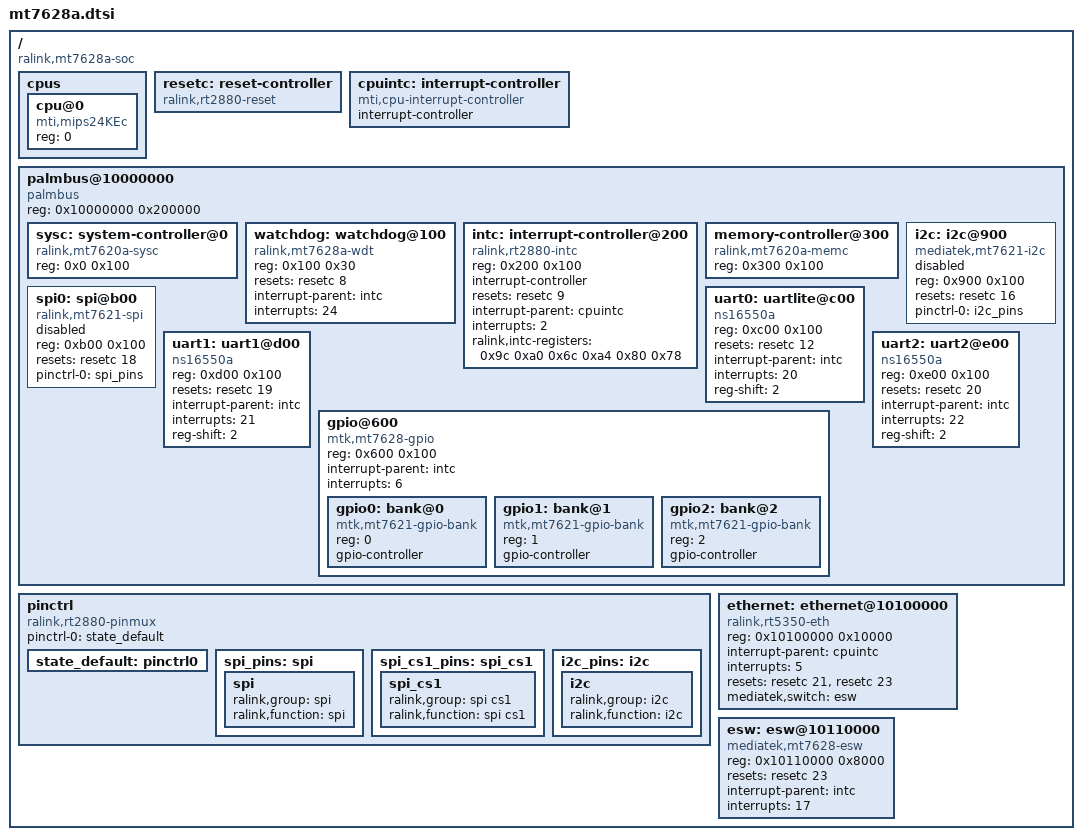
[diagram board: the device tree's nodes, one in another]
/ {
	#address-cells = <1>;
	#size-cells = <1>;
	compatible = "ralink,mt7628a-soc", "ralink,mt7688-soc";

	cpus {
		#address-cells = <1>;
		#size-cells = <0>;

		cpu@0 {
			compatible = "mti,mips24KEc";
			device_type = "cpu";
			reg = <0>;
		};
	};

	resetc: reset-controller {
		compatible = "ralink,rt2880-reset";
		#reset-cells = <1>;
	};

	cpuintc: interrupt-controller {
		#address-cells = <0>;
		#interrupt-cells = <1>;
		interrupt-controller;
		compatible = "mti,cpu-interrupt-controller";
	};

	palmbus@10000000 {
		compatible = "palmbus";
		reg = <0x10000000 0x200000>;
		ranges = <0x0 0x10000000 0x1FFFFF>;

		#address-cells = <1>;
		#size-cells = <1>;

		sysc: system-controller@0 {
			compatible = "ralink,mt7620a-sysc", "syscon";
			reg = <0x0 0x100>;
		};

		watchdog: watchdog@100 {
			compatible = "ralink,mt7628a-wdt", "mediatek,mt7621-wdt";
			reg = <0x100 0x30>;

			resets = <&resetc 8>;
			reset-names = "wdt";

			interrupt-parent = <&intc>;
			interrupts = <24>;
		};

		intc: interrupt-controller@200 {
			compatible = "ralink,rt2880-intc";
			reg = <0x200 0x100>;

			interrupt-controller;
			#interrupt-cells = <1>;

			resets = <&resetc 9>;
			reset-names = "intc";

			interrupt-parent = <&cpuintc>;
			interrupts = <2>;

			ralink,intc-registers = <0x9c 0xa0
						 0x6c 0xa4
						 0x80 0x78>;
		};

		memory-controller@300 {
			compatible = "ralink,mt7620a-memc";
			reg = <0x300 0x100>;
		};

		i2c: i2c@900 {
			compatible = "mediatek,mt7621-i2c";
			reg = <0x900 0x100>;

			resets = <&resetc 16>;
			reset-names = "i2c";

			#address-cells = <1>;
			#size-cells = <0>;

			status = "disabled";

			pinctrl-names = "default";
			pinctrl-0 = <&i2c_pins>;
		};

		spi0: spi@b00 {
			compatible = "ralink,mt7621-spi";
			reg = <0xb00 0x100>;

			resets = <&resetc 18>;
			reset-names = "spi";

			#address-cells = <1>;
			#size-cells = <0>;

			pinctrl-names = "default";
			pinctrl-0 = <&spi_pins>;

			status = "disabled";
		};

		uart0: uartlite@c00 {
			compatible = "ns16550a";
			reg = <0xc00 0x100>;

			resets = <&resetc 12>;
			reset-names = "uart0";

			interrupt-parent = <&intc>;
			interrupts = <20>;

			reg-shift = <2>;
		};

		uart1: uart1@d00 {
			compatible = "ns16550a";
			reg = <0xd00 0x100>;

			resets = <&resetc 19>;
			reset-names = "uart1";

			interrupt-parent = <&intc>;
			interrupts = <21>;

			reg-shift = <2>;
		};

		uart2: uart2@e00 {
			compatible = "ns16550a";
			reg = <0xe00 0x100>;

			resets = <&resetc 20>;
			reset-names = "uart2";

			interrupt-parent = <&intc>;
			interrupts = <22>;

			reg-shift = <2>;
		};

		gpio@600 {
			#address-cells = <1>;
			#size-cells = <0>;

			compatible = "mtk,mt7628-gpio", "mtk,mt7621-gpio";
			reg = <0x600 0x100>;

			interrupt-parent = <&intc>;
			interrupts = <6>;

			gpio0: bank@0 {
				reg = <0>;
				compatible = "mtk,mt7621-gpio-bank";
				gpio-controller;
				#gpio-cells = <2>;
			};

			gpio1: bank@1 {
				reg = <1>;
				compatible = "mtk,mt7621-gpio-bank";
				gpio-controller;
				#gpio-cells = <2>;
			};

			gpio2: bank@2 {
				reg = <2>;
				compatible = "mtk,mt7621-gpio-bank";
				gpio-controller;
				#gpio-cells = <2>;
			};
		};
	};

	pinctrl: pinctrl {
		compatible = "ralink,rt2880-pinmux";
		pinctrl-names = "default";
		pinctrl-0 = <&state_default>;

		state_default: pinctrl0 {
		};

		spi_pins: spi {
			spi {
				ralink,group = "spi";
				ralink,function = "spi";
			};
		};

		spi_cs1_pins: spi_cs1 {
			spi_cs1 {
				ralink,group = "spi cs1";
				ralink,function = "spi cs1";
			};
		};

		i2c_pins: i2c {
			i2c {
				ralink,group = "i2c";
				ralink,function = "i2c";
			};
		};
	};

	ethernet: ethernet@10100000 {
		compatible = "ralink,rt5350-eth";
		reg = <0x10100000 0x10000>;

		interrupt-parent = <&cpuintc>;
		interrupts = <5>;

		resets = <&resetc 21 &resetc 23>;
		reset-names = "fe", "esw";

		mediatek,switch = <&esw>;
	};

	esw: esw@10110000 {
		compatible = "mediatek,mt7628-esw", "ralink,rt3050-esw";
		reg = <0x10110000 0x8000>;

		resets = <&resetc 23>;
		reset-names = "esw";

		interrupt-parent = <&intc>;
		interrupts = <17>;
	};


};
